# STM32G070 register map
File version: 1.9
CPU: CM0 r0p1, little endian, MPU, no FPU, 2 interrupt priority bits
Registers are 32-bit, read-write, reset 0x0 unless marked. A register's access mark holds for its fields unless they carry their own. Offsets are from the block's base; [hi:lo] are bit positions.

## WWDG — System window watchdog
Base 0x40002C00
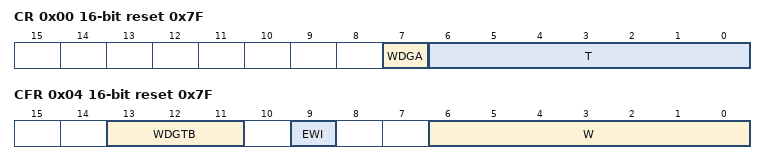
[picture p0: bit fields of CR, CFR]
0x00 CR 16-bit reset 0x7F — Control register
  [7] WDGA — Activation bit
    0=Disabled (Watchdog disabled); 1=Enabled (Watchdog enabled)
  [6:0] T — 7-bit counter (MSB to LSB)
0x04 CFR 16-bit reset 0x7F — Configuration register
  [13:11] WDGTB — Timer base
    0=Div1 (Counter clock (PCLK1 div 4096) div 1); 1=Div2 (Counter clock (PCLK1 div 4096) div 2); 2=Div4 (Counter clock (PCLK1 div 4096) div 4); 3=Div8 (Counter clock (PCLK1 div 4096) div 8); 4=Div16 (Counter clock (PCLK1 div 4096) div 16); 5=Div32 (Counter clock (PCLK1 div 4096) div 32); 6=Div64 (Counter clock (PCLK1 div 4096) div 64); 7=Div128 (Counter clock (PCLK1 div 4096) div 128)
  [9] EWI — Early wakeup interrupt
    on write: 1=Enable (interrupt occurs whenever the counter reaches the value 0x40)
  [6:0] W — 7-bit window value
0x08 SR 16-bit — Status register
  [0] EWIF write-0-clears — Early wakeup interrupt flag
    on read: 0=Finished (The EWI Interrupt Service Routine has been serviced); 1=Pending (The EWI Interrupt Service Routine has been triggered) | on write: 0=Finished (The EWI Interrupt Service Routine has been serviced)

## FLASH
Base 0x40022000
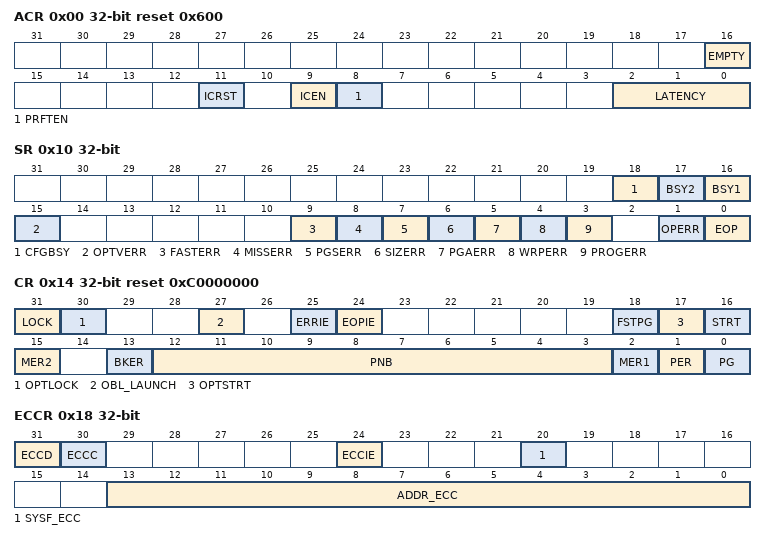
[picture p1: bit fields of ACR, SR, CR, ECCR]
0x00 ACR reset 0x600 — Access control register
  [16] EMPTY — Flash User area empty
  [11] ICRST — Instruction cache reset
  [9] ICEN — Instruction cache enable
  [8] PRFTEN — Prefetch enable
  [2:0] LATENCY
0x08 KEYR wo — Flash key register
  [31:0] KEY — KEYR
0x0C OPTKEYR wo — Option byte key register
  [31:0] OPTKEY — Option byte key
0x10 SR — Status register
  [18] CFGBSY — Programming or erase configuration busy.
  [17] BSY2
  [16] BSY1
  [15] OPTVERR — Option and Engineering bits loading validity error
  [9] FASTERR — Fast programming error
  [8] MISSERR — Fast programming data miss error
  [7] PGSERR — Programming sequence error
  [6] SIZERR — Size error
  [5] PGAERR — Programming alignment error
  [4] WRPERR — Write protected error
  [3] PROGERR — Programming error
  [1] OPERR — Operation error
  [0] EOP — End of operation
0x14 CR reset 0xC0000000 — Flash control register
  [31] LOCK — FLASH_CR Lock
  [30] OPTLOCK — Options Lock
  [27] OBL_LAUNCH — Force the option byte loading
  [25] ERRIE — Error interrupt enable
  [24] EOPIE — End of operation interrupt enable
  [18] FSTPG — Fast programming
  [17] OPTSTRT — Options modification start
  [16] STRT — Start
  [15] MER2
  [13] BKER
  [12:3] PNB — Page number
  [2] MER1 — Mass erase
  [1] PER — Page erase
  [0] PG — Programming
0x18 ECCR access per field — Flash ECC register
  [31] ECCD rw — ECC detection
  [30] ECCC rw — ECC correction
  [24] ECCIE rw — ECC correction interrupt enable
  [20] SYSF_ECC ro — ECC fail for Corrected ECC Error or Double ECC Error in info block
  [13:0] ADDR_ECC ro — ECC fail address
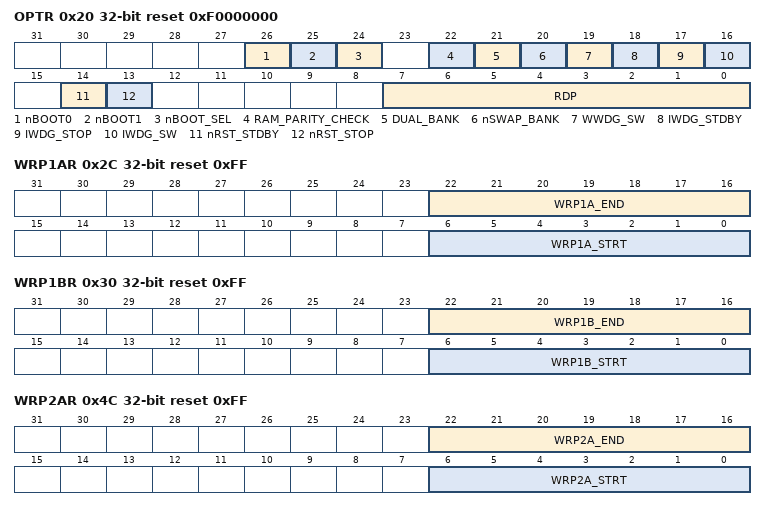
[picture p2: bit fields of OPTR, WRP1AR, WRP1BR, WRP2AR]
0x20 OPTR reset 0xF0000000 — Flash option register
  [26] nBOOT0 — nBOOT0 option bit
  [25] nBOOT1 — Boot configuration
  [24] nBOOT_SEL
  [22] RAM_PARITY_CHECK — SRAM parity check control
  [21] DUAL_BANK
  [20] nSWAP_BANK
  [19] WWDG_SW — Window watchdog selection
  [18] IWDG_STDBY — Independent watchdog counter freeze in Standby mode
  [17] IWDG_STOP — Independent watchdog counter freeze in Stop mode
  [16] IWDG_SW — Independent watchdog selection
  [14] nRST_STDBY
  [13] nRST_STOP
  [7:0] RDP — Read protection level
0x2C WRP1AR reset 0xFF — Flash WRP area A address register
  [22:16] WRP1A_END — WRP area A end offset
  [6:0] WRP1A_STRT — WRP area A start offset
0x30 WRP1BR reset 0xFF — Flash WRP area B address register
  [22:16] WRP1B_END — WRP area B end offset
  [6:0] WRP1B_STRT — WRP area B start offset
0x4C WRP2AR reset 0xFF — FLASH WRP2 area A address register
  [22:16] WRP2A_END, [6:0] WRP2A_STRT
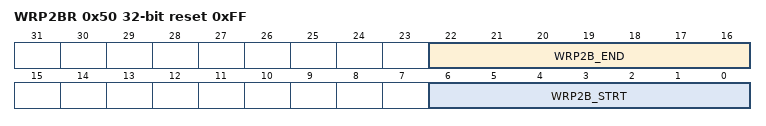
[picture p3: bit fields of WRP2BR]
0x50 WRP2BR reset 0xFF — FLASH WRP2 area B address register
  [22:16] WRP2B_END, [6:0] WRP2B_STRT
